# psoc4000t register map
Vendor: Cypress Semiconductor; Series: PSoC4000T; File version: 1.0
CPU: CM0PLUS r0p1, little endian, no MPU, no FPU, VTOR, 2 interrupt priority bits
Registers are 32-bit, read-write, reset 0x0 unless marked. A register's access mark holds for its fields unless they carry their own. Offsets are from the block's base; [hi:lo] are bit positions; {n}, {i} and the like mark numbered series; 'fields as' and 'values as' point back to an identical list; <NAME> marks a mode.

## CPUSS — CPU Subsystem
Base 0x40100000
0x00 CONFIG — Configuration register
  [0] VECT_IN_RAM — 0': Vector Table is located at 0x0000:0000 in flash '1': Vector Table is located at 0x2000:0000 in SRAM Note that vectors for RESET and FAULT are always fetched from ROM. Value in flash/RAM is ignored for these vectors.
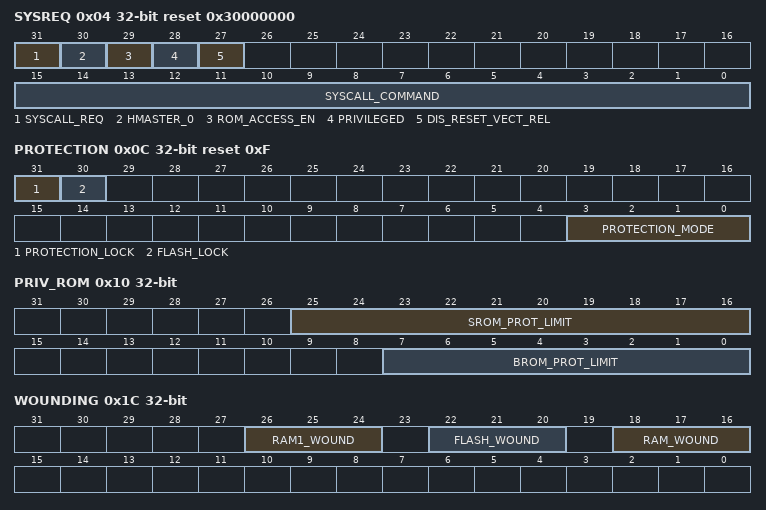
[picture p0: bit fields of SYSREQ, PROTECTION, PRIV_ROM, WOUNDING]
0x04 SYSREQ reset 0x30000000 — SYSCALL control register
  [31] SYSCALL_REQ — CPU/DAP writes a '1' to this field to request a SystemCall. The HMASTER_0 field indicates the source of the write access. Setting this field to '1' immediate results in a NMI. The SystemCall NMI interrupt handler sets this field to '0' after servicing the request.
  [30] HMASTER_0 ro — Indicates the source of the write access to the SYSREQ register. '0': CPU write access. '1': DAP write access. For a SW write to the SYSREQ register, the HW will update this field based on the value of SYSCALL_REQ. SYSCALL_REQ = 0 : the current source of write access is captured. SYSCALL_REQ = 1 : the previous value (captured when SYSCALL_REQ was 0), is retained/maintained until the next SW write to this register.
  [29] ROM_ACCESS_EN ro — Indicates that executing from Boot ROM is enabled. HW sets this field to '1', on reset or when the SystemCall NMI vector is fetched from Boot ROM. HW sets this field to '0', when the CPU is NOT executing from either Boot or System ROM. This bit is used for debug purposes only.
  [28] PRIVILEGED — Indicates whether the system is in privileged ('1') or user mode ('0'). Only CPU SW executing from ROM can set this field to '1' when ROM_ACCESS_EN is '1' (the CPU is executing a SystemCall NMI interrupt handler). Any other write to this field sets is to '0'. This field is used as the AHB-Lite hprot[1] signal to implement Cypress proprietary user/privileged modes. These modes are used to enable/disable access to specific MMIO registers and memory regions.
  [27] DIS_RESET_VECT_REL — Disable Reset Vector fetch relocation: '0': CPU accesses to locations 0x0000:0000 - 0x0000:0007 are redirected to ROM. '1': CPU accesses to locations 0x0000:0000 - 0x0000:0007 are made to flash. Note that this field defaults to '0' on reset, ensuring actual reset vector fetches are always made to ROM. Note that this field does not affect DAP accesses. Flash DfT routines may set this bit to '1' to enable uninhibited read-back of programmed data in the first flash page.
  [15:0] SYSCALL_COMMAND — Opcode of the system call being requested.
0x08 SYSARG — SYSARG control register
  [31:0] SYSCALL_ARG — Argument to System Call specified in SYSREQ. Semantics of argument depends on system call made. Typically a pointer to a parameter block.
0x0C PROTECTION reset 0xF — Protection control register
  [31] PROTECTION_LOCK — Setting this field will block (ignore) any further writes to the PROTECTION_MODE field in this register. Once '1', this field cannot be cleared.
  [30] FLASH_LOCK — Setting this bit will force SPCIF.ADDRESS.AXA to be ignored, which prevents SM Flash from being erased or overwritten. It is used to indicate the DEAD protection mode. Writes to this field are ignored when PROTECTION_LOCK is '1'
  [3:0] PROTECTION_MODE — Current protection mode; this field is available as a global signal everywhere in the system. Writes to this field are ignored when PROTECTION_LOCK is '1': 0b1xxx: BOOT 0b01xx: KILL 0b001x: PROTECTED 0b0001: OPEN 0b0000: VIRGIN (also used for DEAD mode, but then FLASH_LOCK is also set)
0x10 PRIV_ROM — ROM privilege register
  [25:16] SROM_PROT_LIMIT — Indicates the limit where the privileged area of System ROM partition starts in increments of 256 Bytes. The limit is wrt. the start of the ROM memory (start of the Boot ROM partition). SROM_PROT_LIMIT * 256 Byte <= 'Boot ROM partition capacity': Entire System ROM is Privileged. SROM_PROT_LIMIT * 256 Byte > 'Boot ROM partition capacity': First SROM_PROT_LIMIT * 256 - 'Boot ROM partition capacity' Bytes are User accessible. ... SROM_PROT_LIMIT >= 'ROM capacity': Entire System ROM is user mode accessible.
  [7:0] BROM_PROT_LIMIT — Indicates the limit where the privileged area of the Boot ROM partition starts in increments of 256 Bytes. '0': Entire Boot ROM is Privileged. '1': First 256 Bytes are User accessible. ... BROM_PROT_LIMIT >= 'Boot ROM partition capacity': Entire Boot ROM partition is user mode accessible.
0x14 PRIV_RAM — RAM privilege register
  [8:0] RAM_PROT_LIMIT — Indicates the limit where the privileged area of SRAM starts in increments of 256 Bytes. '0': Entire SRAM is Privileged. '1': First 256 Bytes are User accessible. Any number larger than the size of the SRAM indicates that the entire SRAM is user mode accessible.
0x18 PRIV_FLASH — Flash privilege register
  [11:0] FLASH_PROT_LIMIT — Indicates the limit where the privileged area of flash starts in increments of 256 Bytes. '0': Entire flash is Privileged. '1': First 256 Bytes are User accessible. Any number larger than the size of the flash indicates that the entire flash is user mode accessible. Note that Supervisory rows are always User accessible. If FLASH_PROT_LIMIT defines a non-empty privileged area, the boot ROM will assume that a system call table exists at the beginning of the Flash privileged area and use it for all SystemCalls made using SYSREQ.
0x1C WOUNDING
  [26:24] RAM1_WOUND — Wounding of RAM 1 (see description of RAM_WOUND).
  [22:20] FLASH_WOUND — Indicates the amount of accessible flash in this part. The value in this field is effectively write-once (it is only possible to set bits, not clear them). The remainder portion of flash is not accessible and will return an AHB-Lite bus error. '0': entire memory accessible '1': first 1/2 of the memory accessible '2': first 1/4 of the memory accessible '3': first 1/8 of the memory accessible '4': first 1/16 of the memory accessible '5': first 1/32 of the memory accessible '6': first 1/64 of the memory accessible '7': first 1/128 of the memory accessible (used for the DEAD protection mode)
  [18:16] RAM_WOUND — Indicates the amount of accessible RAM 0 memory capacity in this part. The value in this field is effectively write-once (it is only possible to set bits, not clear them). The remainder portion of SRAM is not accessible and will return an AHB-Lite bus error. '0': entire memory accessible '1': first 1/2 of the memory accessible '2': first 1/4 of the memory accessible '3': first 1/8 of the memory accessible '4': first 1/16 of the memory accessible '5': first 1/32 of the memory accessible '6': first 1/64 of the memory accessible '7': first 1/128 of the memory accessible
0x20 INT_SEL — Interrupt multiplexer select register
  [31:0] DSI — Specifies interrupt source: '0': Fixed Function. '1': DSI. When changing the source of a specific interrupt, it is advised to temporarily disable the interrupt using the CM0 NVIC's CLRENA and SETENA interrupt enable clear and set registers to prevent a spurious interrupt activation. In addition, the CM0 NVIC's CLRPEND interrupt pending clear register should be used clear a pending interrupt before re-enabling the interrupt.
0x24 INT_MODE — DSI interrupt pulse mode register
  [31:0] DSI_INT_PULSE — Specifies DSI interrupt format: '0': level sensitive; i.e. no pulse generator. '1': pulse generator on rising edge.
0x28 NMI_MODE — DSI NMI pulse mode register
  [0] DSI_NMI_PULSE — Specifies DSI NMI format: '0': level sensitive; i.e. no pulse generator. '1': pulse generator on rising edge.
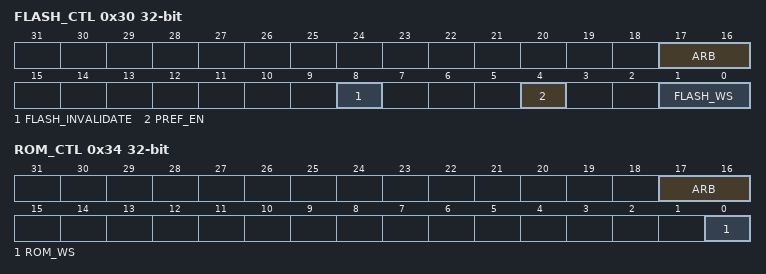
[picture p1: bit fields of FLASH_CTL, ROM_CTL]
0x30 FLASH_CTL — FLASH control register
  [17:16] ARB — Arbitration policy: '0': CPU has priority '1': DW/DMA has priority '2': Roundrobin '3': Roundrobin - sticky
  [8] FLASH_INVALIDATE — 1': Invalidates the content of the flash controller's buffers.
  [4] PREF_EN — Prefetch enable: '0': disabled. This is a desirable setting when FLASH_WS is '0' or when predictable execution time is required. '1': enabled.
  [1:0] FLASH_WS — Amount of ROM wait states: '0': 0 wait states (fast flash: [0, 24] MHz system frequency, slow flash: [0, 16] MHz system frequency) '1': 1 wait state (fast flash: [24, 48] MHz system frequency, slow flash: [16, 32] MHz system frequency) '2': 2 wait states (slow flash: [32, 48] MHz system frequency) '3': 3 wait states (can be used to give more time for flash access if 2 wait states are not sufficient)
0x34 ROM_CTL — ROM control register
  [17:16] ARB — Arbitration policy: '0': CPU has priority '1': DW/DMA has priority '2': Roundrobin '3': Roundrobin - sticky
  [0] ROM_WS — Amount of ROM wait states: '0': 0 wait states. Use this setting for newer, faster ROM design. Use this setting for older, slower ROM design and frequencies in the range [0, 24] MHz. '1': 1 wait state. Use this setting for older, slower ROM design and frequencies in the range <24, 48] MHz. CPUSSv2 supports two types of ROM memory: an older, slower design (operating at up to 24 MHz) and a newer, faster design (operating at up to 48 MHz). The older design requires 1 wait state for frequencies above 24 MHz. The newer design never requires wait states. All chips after Street Fighter will use the newer design. As a result, all chips after Street Fighter can always use 0 wait states.
0x38 RAM_CTL — RAM control register
  [17:16] ARB — Arbitration policy: '0': CPU has priority '1': DW/DMA has priority '2': Roundrobin '3': Roundrobin - sticky
0x3C DMAC_CTL — DMA controller register
  fields as RAM_CTL
0xA0 PRIV_RAM1 reset 0x1FF — RAM 1 privilege register
  [8:0] RAM_PROT_LIMIT — See description of PRIV_RAM.RAM_PROT_LIMIT. Note that the reset value is 0x1ff, indicating that the complete RAM 1 memory capacity is User accessible.
0xA4 RAM1_CTL — RAM 1 control register
  [17:16] ARB — Arbitration policy (for RAM controller 1): '0': CPU has priority '1': DW/DMA has priority '2': Roundrobin '3': Roundrobin - sticky
0xB0 MTB_CTL — MTB control register
  [0] CPU_HALT_TSTOP_EN — 1': Enable CPU Halt to stop MTB trace. ('HALTED' output of CM0+ can stop the trace when high/'1') '0': 'HALTED' output of CM0+ can not strop trace.
{0x100+4i} SL_CTL[{i}] (i=0..23) — Slave control register
  [17:16] ARB — Arbitration policy: '0': CPU priority '1': DMA priority '2': Roundrobin '3': Roundrobin - sticky

## SPCIF — Flash Control Interface
Base 0x40110000
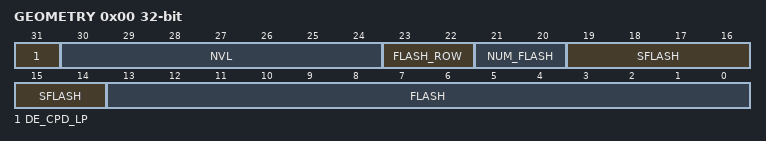
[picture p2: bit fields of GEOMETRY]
0x00 GEOMETRY (reset mask 0x80000000) — Flash/NVL geometry information
  [31] DE_CPD_LP — 0': SRAM busy wait loop has not been copied. '1': Busy wait loop has been written into SRAM.
  [30:24] NVL ro — NVLatch size in Byte multiples (chip dependent): '0': 0 Bytes '1': 1 Byte ... '127': 127 Bytes
  [23:22] FLASH_ROW ro — Page size in 64 Byte multiples (chip dependent): '0': 64 byte '1': 128 byte '2': 192 byte '3': 256 byte The page size is used to determine the number of Bytes in a page for Flash page based operations (e.g. PGM_PAGE). Note: the field name FLASH_ROW is misleading, as this field specifies the number of Bytes in a page, rather than the number of Bytes in a row. In a single plane flash macro architecture, a page consists of a single row. However, in a multi plane flash macro architecture, a page consists of multiple rows from different planes.
  [21:20] NUM_FLASH ro — Number of flash macros (chip dependent): '0': 1 flash macro '1': 2 flash macros '2': 3 flash macros '3': 4 flash macros
  [19:14] SFLASH ro — Supervisory flash capacity in 256 Byte multiples (chip dependent). If multiple flash macros are present, this field provides the supervisory flash capacity of all flash macros together: '0': 256 Bytes. '1': 2*256 Bytes. ... '63': 64*256 Bytes.
  [13:0] FLASH ro — Regular flash capacity in 256 Byte multiples (chip dependent). If multiple flash macros are present, this field provides the flash capacity of all flash macros together: '0': 256 Bytes. '1': 2*256 Bytes. ... '16383': 16384*256 Bytes.
0x1C NVL_WR_DATA — NVL write data register
  [7:0] DATA — Data to be written to NVLatch array
0x7F0 INTR — SPCIF interrupt request register
  [0] TIMER — Timer counter value reaches '0'. Set to '1', when event is detected. Write INTR field with '1', to clear bit. Write INTR_SET field with '1', to set bit.
0x7F4 INTR_SET — SPCIF interrupt set request register
  [0] TIMER — Write INTR_SET field with '1' to set corresponding INTR field.
0x7F8 INTR_MASK — SPCIF interrupt mask register
  [0] TIMER — Mask for corresponding field in INTR register.
0x7FC INTR_MASKED ro — SPCIF interrupt masked request register
  [0] TIMER — Logical and of corresponding request and mask fields.
